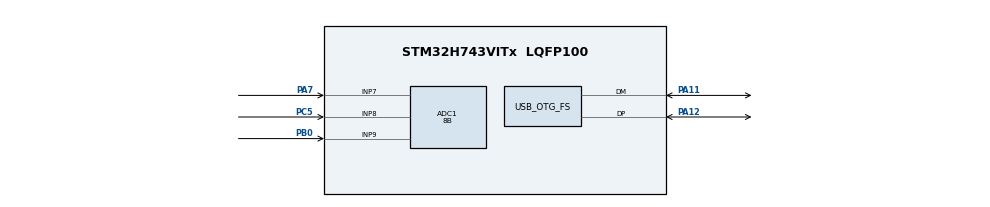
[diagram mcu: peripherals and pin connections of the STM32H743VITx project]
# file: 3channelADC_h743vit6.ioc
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ADC1.Channel-0\#ChannelRegularConversion=ADC_CHANNEL_7
ADC1.Channel-1\#ChannelRegularConversion=ADC_CHANNEL_8
ADC1.Channel-2\#ChannelRegularConversion=ADC_CHANNEL_9
ADC1.ContinuousConvMode=DISABLE
ADC1.EOCSelection=ADC_EOC_SEQ_CONV
ADC1.NbrOfConversion=3
ADC1.NbrOfConversionFlag=1
ADC1.Offset-2\#ChannelRegularConversion=0
ADC1.OffsetNumber-0\#ChannelRegularConversion=ADC_OFFSET_NONE
ADC1.OffsetNumber-1\#ChannelRegularConversion=ADC_OFFSET_NONE
ADC1.OffsetNumber-2\#ChannelRegularConversion=ADC_OFFSET_NONE
ADC1.Rank-0\#ChannelRegularConversion=1
ADC1.Rank-1\#ChannelRegularConversion=2
ADC1.Rank-2\#ChannelRegularConversion=3
ADC1.Resolution=ADC_RESOLUTION_8B
ADC1.SamplingTime-0\#ChannelRegularConversion=ADC_SAMPLETIME_1CYCLE_5
ADC1.SamplingTime-1\#ChannelRegularConversion=ADC_SAMPLETIME_1CYCLE_5
ADC1.SamplingTime-2\#ChannelRegularConversion=ADC_SAMPLETIME_1CYCLE_5
ADC1.master=1
Mcu.Family=STM32H7
Mcu.Name=STM32H743VITx
Mcu.Package=LQFP100
NVIC.OTG_FS_IRQn=true\:0\:0\:false\:false\:true\:false\:true
NVIC.PriorityGroup=NVIC_PRIORITYGROUP_4
PA11.Mode=Device_Only
PA11.Signal=USB_OTG_FS_DM
PA12.Mode=Device_Only
PA12.Signal=USB_OTG_FS_DP
PA13\ (JTMS/SWDIO).Mode=Serial_Wire
PA13\ (JTMS/SWDIO).Signal=DEBUG_JTMS-SWDIO
PA14\ (JTCK/SWCLK).Mode=Serial_Wire
PA14\ (JTCK/SWCLK).Signal=DEBUG_JTCK-SWCLK
PA7.Signal=ADCx_INP7
PB0.Signal=ADCx_INP9
PC14-OSC32_IN\ (OSC32_IN).Mode=LSE-External-Oscillator
PC14-OSC32_IN\ (OSC32_IN).Signal=RCC_OSC32_IN
PC15-OSC32_OUT\ (OSC32_OUT).Mode=LSE-External-Oscillator
PC15-OSC32_OUT\ (OSC32_OUT).Signal=RCC_OSC32_OUT
PC5.Signal=ADCx_INP8
PH0-OSC_IN\ (PH0).Mode=HSE-External-Oscillator
PH0-OSC_IN\ (PH0).Signal=RCC_OSC_IN
PH1-OSC_OUT\ (PH1).Mode=HSE-External-Oscillator
PH1-OSC_OUT\ (PH1).Signal=RCC_OSC_OUT
ProjectManager.HeapSize=0x200
ProjectManager.StackSize=0x400
ProjectManager.TargetToolchain=STM32CubeIDE
RCC.ADCFreq_Value=150000000
RCC.APB1Freq_Value=100000000
RCC.APB2Freq_Value=100000000
RCC.APB3Freq_Value=100000000
RCC.APB4Freq_Value=100000000
RCC.CortexFreq_Value=100000000
RCC.DIVM1=5
RCC.DIVM2=2
RCC.DIVN1=40
RCC.DIVN2=12
RCC.DIVP2=1
RCC.DIVQ1=5
RCC.HCLKFreq_Value=100000000
RCC.PLL2FRACN=0
RCC.PLL3FRACN=0
RCC.PLLFRACN=0
RCC.PLLSourceVirtual=RCC_PLLSOURCE_HSE
RCC.SYSCLKFreq_VALUE=100000000
RCC.SYSCLKSource=RCC_SYSCLKSOURCE_PLLCLK
RCC.USBCLockSelection=RCC_USBCLKSOURCE_HSI48
RCC.USBFreq_Value=48000000
SH.ADCx_INP7.0=ADC1_INP7,IN7-Single-Ended
SH.ADCx_INP8.0=ADC1_INP8,IN8-Single-Ended
SH.ADCx_INP9.0=ADC1_INP9,IN9-Single-Ended
USB_DEVICE.APP_RX_DATA_SIZE-CDC_FS=1000
USB_DEVICE.APP_TX_DATA_SIZE-CDC_FS=1000
USB_DEVICE.CLASS_NAME_FS=CDC
USB_DEVICE.USBD_MAX_STR_DESC_SIZ-CDC_FS=256
USB_DEVICE.VirtualMode-CDC_FS=Cdc
USB_DEVICE.VirtualModeFS=Cdc_FS
USB_OTG_FS.VirtualMode=Device_Only
VP_USB_DEVICE_VS_USB_DEVICE_CDC_FS.Mode=CDC_FS
board=custom

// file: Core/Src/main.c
/* USER CODE BEGIN Header */
/**
  ******************************************************************************
  * @file           : main.c
  * @brief          : Main program body
  ******************************************************************************
  * @attention
  *
  * <h2><center>&copy; Copyright (c) 2020 STMicroelectronics.
  * All rights reserved.</center></h2>
  *
  * This software component is licensed by ST under BSD 3-Clause license,
  * the "License"; You may not use this file except in compliance with the
  * License. You may obtain a copy of the License at:
  *                        opensource.org/licenses/BSD-3-Clause
  *
  ******************************************************************************
  */
/* USER CODE END Header */

#include "main.h"
#include "usb_device.h"

ADC_HandleTypeDef hadc1;

void SystemClock_Config(void);
static void MX_GPIO_Init(void);
static void MX_ADC1_Init(void);

int main(void)
{

  /* MCU Configuration--------------------------------------------------------*/

  /* Reset of all peripherals, Initializes the Flash interface and the Systick. */
  HAL_Init();

  /* Configure the system clock */
  SystemClock_Config();

  /* Initialize all configured peripherals */
  MX_GPIO_Init();
  MX_ADC1_Init();
  MX_USB_DEVICE_Init();
  /* USER CODE BEGIN 2 */
  uint8_t dataFromAdc7 = 0;
  uint8_t dataFromAdc8 = 0;
  uint8_t dataFromAdc9 = 0;
  /* USER CODE END 2 */

  /* Infinite loop */
  /* USER CODE BEGIN WHILE */
  while (1)
  {
	  HAL_ADC_Start(&hadc1);
	  HAL_ADC_PollForConversion(&hadc1,100);
	  dataFromAdc7 = (uint8_t) HAL_ADC_GetValue(&hadc1);
	  dataFromAdc8 = (uint8_t) HAL_ADC_GetValue(&hadc1);
	  dataFromAdc9 = (uint8_t) HAL_ADC_GetValue(&hadc1);
	  HAL_ADC_Stop(&hadc1);
    /* USER CODE END WHILE */

  }
}

void SystemClock_Config(void)
{
  RCC_OscInitTypeDef RCC_OscInitStruct = {0};
  RCC_ClkInitTypeDef RCC_ClkInitStruct = {0};
  RCC_PeriphCLKInitTypeDef PeriphClkInitStruct = {0};

  /** Supply configuration update enable
  */
  HAL_PWREx_ConfigSupply(PWR_LDO_SUPPLY);
  /** Configure the main internal regulator output voltage
  */
  __HAL_PWR_VOLTAGESCALING_CONFIG(PWR_REGULATOR_VOLTAGE_SCALE3);

  while(!__HAL_PWR_GET_FLAG(PWR_FLAG_VOSRDY)) {}
  /** Macro to configure the PLL clock source
  */
  __HAL_RCC_PLL_PLLSOURCE_CONFIG(RCC_PLLSOURCE_HSE);
  /** Initializes the CPU, AHB and APB busses clocks
  */
  RCC_OscInitStruct.OscillatorType = RCC_OSCILLATORTYPE_HSI48|RCC_OSCILLATORTYPE_HSE;
  RCC_OscInitStruct.HSEState = RCC_HSE_ON;
  RCC_OscInitStruct.HSI48State = RCC_HSI48_ON;
  RCC_OscInitStruct.PLL.PLLState = RCC_PLL_ON;
  RCC_OscInitStruct.PLL.PLLSource = RCC_PLLSOURCE_HSE;
  RCC_OscInitStruct.PLL.PLLM = 5;
  RCC_OscInitStruct.PLL.PLLN = 40;
  RCC_OscInitStruct.PLL.PLLP = 2;
  RCC_OscInitStruct.PLL.PLLQ = 5;
  RCC_OscInitStruct.PLL.PLLR = 2;
  RCC_OscInitStruct.PLL.PLLRGE = RCC_PLL1VCIRANGE_2;
  RCC_OscInitStruct.PLL.PLLVCOSEL = RCC_PLL1VCOWIDE;
  RCC_OscInitStruct.PLL.PLLFRACN = 0;
  if (HAL_RCC_OscConfig(&RCC_OscInitStruct) != HAL_OK)
  {
    Error_Handler();
  }
  /** Initializes the CPU, AHB and APB busses clocks
  */
  RCC_ClkInitStruct.ClockType = RCC_CLOCKTYPE_HCLK|RCC_CLOCKTYPE_SYSCLK
                              |RCC_CLOCKTYPE_PCLK1|RCC_CLOCKTYPE_PCLK2
                              |RCC_CLOCKTYPE_D3PCLK1|RCC_CLOCKTYPE_D1PCLK1;
  RCC_ClkInitStruct.SYSCLKSource = RCC_SYSCLKSOURCE_PLLCLK;
  RCC_ClkInitStruct.SYSCLKDivider = RCC_SYSCLK_DIV1;
  RCC_ClkInitStruct.AHBCLKDivider = RCC_HCLK_DIV1;
  RCC_ClkInitStruct.APB3CLKDivider = RCC_APB3_DIV1;
  RCC_ClkInitStruct.APB1CLKDivider = RCC_APB1_DIV1;
  RCC_ClkInitStruct.APB2CLKDivider = RCC_APB2_DIV1;
  RCC_ClkInitStruct.APB4CLKDivider = RCC_APB4_DIV1;

  if (HAL_RCC_ClockConfig(&RCC_ClkInitStruct, FLASH_LATENCY_1) != HAL_OK)
  {
    Error_Handler();
  }
  PeriphClkInitStruct.PeriphClockSelection = RCC_PERIPHCLK_ADC|RCC_PERIPHCLK_USB;
  PeriphClkInitStruct.PLL2.PLL2M = 2;
  PeriphClkInitStruct.PLL2.PLL2N = 12;
  PeriphClkInitStruct.PLL2.PLL2P = 1;
  PeriphClkInitStruct.PLL2.PLL2Q = 2;
  PeriphClkInitStruct.PLL2.PLL2R = 2;
  PeriphClkInitStruct.PLL2.PLL2RGE = RCC_PLL2VCIRANGE_3;
  PeriphClkInitStruct.PLL2.PLL2VCOSEL = RCC_PLL2VCOMEDIUM;
  PeriphClkInitStruct.PLL2.PLL2FRACN = 0;
  PeriphClkInitStruct.UsbClockSelection = RCC_USBCLKSOURCE_HSI48;
  PeriphClkInitStruct.AdcClockSelection = RCC_ADCCLKSOURCE_PLL2;
  if (HAL_RCCEx_PeriphCLKConfig(&PeriphClkInitStruct) != HAL_OK)
  {
    Error_Handler();
  }
  /** Enable USB Voltage detector
  */
  HAL_PWREx_EnableUSBVoltageDetector();
}

static void MX_ADC1_Init(void)
{

  ADC_MultiModeTypeDef multimode = {0};
  ADC_ChannelConfTypeDef sConfig = {0};

  /** Common config
  */
  hadc1.Instance = ADC1;
  hadc1.Init.ClockPrescaler = ADC_CLOCK_ASYNC_DIV32;
  hadc1.Init.Resolution = ADC_RESOLUTION_8B;
  hadc1.Init.ScanConvMode = ADC_SCAN_ENABLE;
  hadc1.Init.EOCSelection = ADC_EOC_SEQ_CONV;
  hadc1.Init.LowPowerAutoWait = DISABLE;
  hadc1.Init.ContinuousConvMode = DISABLE;
  hadc1.Init.NbrOfConversion = 3;
  hadc1.Init.DiscontinuousConvMode = DISABLE;
  hadc1.Init.ExternalTrigConv = ADC_SOFTWARE_START;
  hadc1.Init.ExternalTrigConvEdge = ADC_EXTERNALTRIGCONVEDGE_NONE;
  hadc1.Init.ConversionDataManagement = ADC_CONVERSIONDATA_DR;
  hadc1.Init.Overrun = ADC_OVR_DATA_PRESERVED;
  hadc1.Init.LeftBitShift = ADC_LEFTBITSHIFT_NONE;
  hadc1.Init.OversamplingMode = DISABLE;
  if (HAL_ADC_Init(&hadc1) != HAL_OK)
  {
    Error_Handler();
  }
  /** Configure the ADC multi-mode
  */
  multimode.Mode = ADC_MODE_INDEPENDENT;
  if (HAL_ADCEx_MultiModeConfigChannel(&hadc1, &multimode) != HAL_OK)
  {
    Error_Handler();
  }
  /** Configure Regular Channel
  */
  sConfig.Channel = ADC_CHANNEL_7;
  sConfig.Rank = ADC_REGULAR_RANK_1;
  sConfig.SamplingTime = ADC_SAMPLETIME_1CYCLE_5;
  sConfig.SingleDiff = ADC_SINGLE_ENDED;
  sConfig.OffsetNumber = ADC_OFFSET_NONE;
  sConfig.Offset = 0;
  if (HAL_ADC_ConfigChannel(&hadc1, &sConfig) != HAL_OK)
  {
    Error_Handler();
  }
  /** Configure Regular Channel
  */
  sConfig.Channel = ADC_CHANNEL_8;
  sConfig.Rank = ADC_REGULAR_RANK_2;
  if (HAL_ADC_ConfigChannel(&hadc1, &sConfig) != HAL_OK)
  {
    Error_Handler();
  }
  /** Configure Regular Channel
  */
  sConfig.Channel = ADC_CHANNEL_9;
  sConfig.Rank = ADC_REGULAR_RANK_3;
  if (HAL_ADC_ConfigChannel(&hadc1, &sConfig) != HAL_OK)
  {
    Error_Handler();
  }

}

static void MX_GPIO_Init(void)
{

  /* GPIO Ports Clock Enable */
  __HAL_RCC_GPIOC_CLK_ENABLE();
  __HAL_RCC_GPIOH_CLK_ENABLE();
  __HAL_RCC_GPIOA_CLK_ENABLE();
  __HAL_RCC_GPIOB_CLK_ENABLE();

}

void Error_Handler(void)
{
}

/************************ (C) COPYRIGHT STMicroelectronics *****END OF FILE****/
